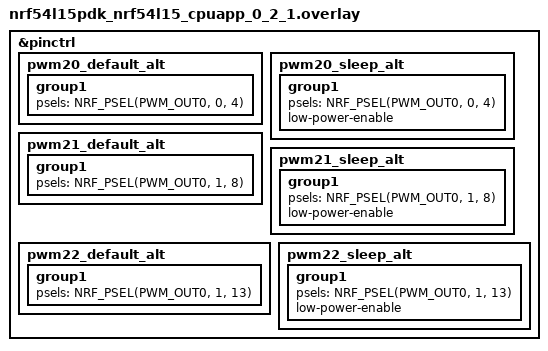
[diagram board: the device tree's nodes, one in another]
/*
 * Copyright (c) 2024 Nordic Semiconductor ASA
 *
 * SPDX-License-Identifier: LicenseRef-Nordic-5-Clause
 */

&pinctrl {
	pwm20_default_alt: pwm20_default_alt {
		group1 {
			psels = <NRF_PSEL(PWM_OUT0, 0, 4)>;
		};
	};

	pwm20_sleep_alt: pwm20_sleep_alt {
		group1 {
			psels = <NRF_PSEL(PWM_OUT0, 0, 4)>;
			low-power-enable;
		};
	};

	pwm21_default_alt: pwm21_default_alt {
		group1 {
			psels = <NRF_PSEL(PWM_OUT0, 1, 8)>;
		};
	};

	pwm21_sleep_alt: pwm21_sleep_alt {
		group1 {
			psels = <NRF_PSEL(PWM_OUT0, 1, 8)>;
			low-power-enable;
		};
	};

	pwm22_default_alt: pwm22_default_alt {
		group1 {
			psels = <NRF_PSEL(PWM_OUT0, 1, 13)>;
		};
	};

	pwm22_sleep_alt: pwm22_sleep_alt {
		group1 {
			psels = <NRF_PSEL(PWM_OUT0, 1, 13)>;
			low-power-enable;
		};
	};
};
